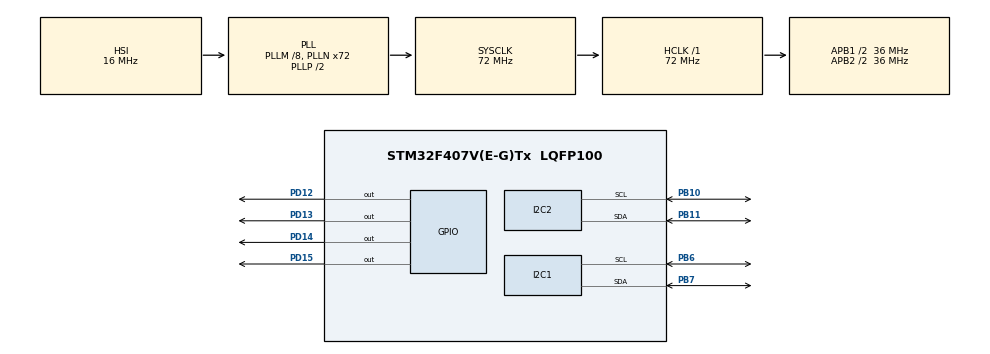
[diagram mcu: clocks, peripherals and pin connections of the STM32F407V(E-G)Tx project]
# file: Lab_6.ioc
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Mcu.Family=STM32F4
Mcu.Name=STM32F407V(E-G)Tx
Mcu.Package=LQFP100
NVIC.I2C1_ER_IRQn=true\:0\:0\:false\:true\:true\:2\:true\:true\:true
NVIC.I2C1_EV_IRQn=true\:0\:0\:false\:true\:true\:1\:true\:true\:true
NVIC.I2C2_ER_IRQn=true\:0\:0\:false\:false\:true\:true\:true\:true
NVIC.I2C2_EV_IRQn=true\:0\:0\:false\:false\:true\:true\:true\:true
NVIC.PriorityGroup=NVIC_PRIORITYGROUP_0
PA13.Mode=Trace_Asynchronous_SW
PA13.Signal=SYS_JTMS-SWDIO
PA14.Mode=Trace_Asynchronous_SW
PA14.Signal=SYS_JTCK-SWCLK
PB10.GPIO_Pu=GPIO_PULLUP
PB10.Mode=I2C
PB10.Signal=I2C2_SCL
PB11.GPIO_Pu=GPIO_PULLUP
PB11.Mode=I2C
PB11.Signal=I2C2_SDA
PB3.Mode=Trace_Asynchronous_SW
PB3.Signal=SYS_JTDO-SWO
PB6.GPIO_Mode=GPIO_MODE_AF_OD
PB6.GPIO_Pu=GPIO_PULLUP
PB6.GPIO_Speed=GPIO_SPEED_FREQ_VERY_HIGH
PB6.Mode=I2C
PB6.Signal=I2C1_SCL
PB7.GPIO_Mode=GPIO_MODE_AF_OD
PB7.GPIO_Pu=GPIO_PULLUP
PB7.GPIO_Speed=GPIO_SPEED_FREQ_VERY_HIGH
PB7.Mode=I2C
PB7.Signal=I2C1_SDA
PD12.Signal=GPIO_Output
PD13.Signal=GPIO_Output
PD14.Signal=GPIO_Output
PD15.Signal=GPIO_Output
ProjectManager.HeapSize=0x200
ProjectManager.StackSize=0x400
ProjectManager.TargetToolchain=STM32CubeIDE
RCC.48MHZClocksFreq_Value=20571428.57142857
RCC.AHBFreq_Value=72000000
RCC.APB1CLKDivider=RCC_HCLK_DIV2
RCC.APB1Freq_Value=36000000
RCC.APB1TimFreq_Value=72000000
RCC.APB2CLKDivider=RCC_HCLK_DIV2
RCC.APB2Freq_Value=36000000
RCC.APB2TimFreq_Value=72000000
RCC.CortexFreq_Value=72000000
RCC.HCLKFreq_Value=72000000
RCC.HSE_VALUE=8000000
RCC.HSI_VALUE=16000000
RCC.PLLM=8
RCC.PLLN=72
RCC.PLLQ=7
RCC.SYSCLKFreq_VALUE=72000000
RCC.SYSCLKSource=RCC_SYSCLKSOURCE_PLLCLK
RCC.VCOOutputFreq_Value=144000000
board=STM32F407G-DISC1

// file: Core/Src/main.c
/* USER CODE BEGIN Header */
/**
  ******************************************************************************
  * @file           : main.c
  * @brief          : Main program body
  ******************************************************************************
  * @attention
  *
  * Copyright (c) 2024 STMicroelectronics.
  * All rights reserved.
  *
  * This software is licensed under terms that can be found in the LICENSE file
  * in the root directory of this software component.
  * If no LICENSE file comes with this software, it is provided AS-IS.
  *
  ******************************************************************************
  */
/* USER CODE END Header */
#include "main.h"

I2C_HandleTypeDef hi2c1;
I2C_HandleTypeDef hi2c2;

/* USER CODE BEGIN PV */
uint8_t receivedData;
/* USER CODE END PV */

void SystemClock_Config(void);
static void MX_GPIO_Init(void);
static void MX_I2C1_Init(void);
static void MX_I2C2_Init(void);
static void MX_NVIC_Init(void);

int main(void)
{

  /* MCU Configuration--------------------------------------------------------*/

  /* Reset of all peripherals, Initializes the Flash interface and the Systick. */
  HAL_Init();

  /* Configure the system clock */
  SystemClock_Config();

  /* Initialize all configured peripherals */
  MX_GPIO_Init();
  MX_I2C1_Init();
  MX_I2C2_Init();

  /* Initialize interrupts */
  MX_NVIC_Init();
  /* USER CODE BEGIN 2 */
  //HAL_I2C_EnableListen_IT(&hi2c1);
  /* USER CODE END 2 */

  /* Infinite loop */
  while (1)
  {

    /* USER CODE BEGIN 3 */
	  if(HAL_I2C_Slave_Receive(&hi2c1, (uint8_t *)&receivedData, sizeof(receivedData),1000)== HAL_OK){
		  GPIOD->ODR &= ~(GPIO_ODR_OD12 |GPIO_ODR_OD13 |GPIO_ODR_OD14 |GPIO_ODR_OD15 );
		  GPIOD->ODR |= (receivedData<<12);
	  }
//	  else{
//		  HAL_GPIO_WritePin(GPIOD, GPIO_PIN_12, RESET);
//		  HAL_GPIO_WritePin(GPIOD, GPIO_PIN_14, RESET);
//		  HAL_GPIO_WritePin(GPIOD, GPIO_PIN_15, RESET);
//		  HAL_GPIO_TogglePin(GPIOD, GPIO_PIN_13);
//	  }
  }
  /* USER CODE END 3 */
}

void SystemClock_Config(void)
{
  RCC_OscInitTypeDef RCC_OscInitStruct = {0};
  RCC_ClkInitTypeDef RCC_ClkInitStruct = {0};

  /** Configure the main internal regulator output voltage
  */
  __HAL_RCC_PWR_CLK_ENABLE();
  __HAL_PWR_VOLTAGESCALING_CONFIG(PWR_REGULATOR_VOLTAGE_SCALE1);

  /** Initializes the RCC Oscillators according to the specified parameters
  * in the RCC_OscInitTypeDef structure.
  */
  RCC_OscInitStruct.OscillatorType = RCC_OSCILLATORTYPE_HSI;
  RCC_OscInitStruct.HSIState = RCC_HSI_ON;
  RCC_OscInitStruct.HSICalibrationValue = RCC_HSICALIBRATION_DEFAULT;
  RCC_OscInitStruct.PLL.PLLState = RCC_PLL_ON;
  RCC_OscInitStruct.PLL.PLLSource = RCC_PLLSOURCE_HSI;
  RCC_OscInitStruct.PLL.PLLM = 8;
  RCC_OscInitStruct.PLL.PLLN = 72;
  RCC_OscInitStruct.PLL.PLLP = RCC_PLLP_DIV2;
  RCC_OscInitStruct.PLL.PLLQ = 7;
  if (HAL_RCC_OscConfig(&RCC_OscInitStruct) != HAL_OK)
  {
    Error_Handler();
  }

  /** Initializes the CPU, AHB and APB buses clocks
  */
  RCC_ClkInitStruct.ClockType = RCC_CLOCKTYPE_HCLK|RCC_CLOCKTYPE_SYSCLK
                              |RCC_CLOCKTYPE_PCLK1|RCC_CLOCKTYPE_PCLK2;
  RCC_ClkInitStruct.SYSCLKSource = RCC_SYSCLKSOURCE_PLLCLK;
  RCC_ClkInitStruct.AHBCLKDivider = RCC_SYSCLK_DIV1;
  RCC_ClkInitStruct.APB1CLKDivider = RCC_HCLK_DIV2;
  RCC_ClkInitStruct.APB2CLKDivider = RCC_HCLK_DIV2;

  if (HAL_RCC_ClockConfig(&RCC_ClkInitStruct, FLASH_LATENCY_2) != HAL_OK)
  {
    Error_Handler();
  }
}

/**
  * @brief NVIC Configuration.
  * @retval None
  */
static void MX_NVIC_Init(void)
{
  /* I2C1_EV_IRQn interrupt configuration */
  HAL_NVIC_SetPriority(I2C1_EV_IRQn, 0, 0);
  HAL_NVIC_EnableIRQ(I2C1_EV_IRQn);
  /* I2C1_ER_IRQn interrupt configuration */
  HAL_NVIC_SetPriority(I2C1_ER_IRQn, 0, 0);
  HAL_NVIC_EnableIRQ(I2C1_ER_IRQn);
}

static void MX_I2C1_Init(void)
{

  hi2c1.Instance = I2C1;
  hi2c1.Init.ClockSpeed = 100000;
  hi2c1.Init.DutyCycle = I2C_DUTYCYCLE_2;
  hi2c1.Init.OwnAddress1 = 0xFA;
  hi2c1.Init.AddressingMode = I2C_ADDRESSINGMODE_7BIT;
  hi2c1.Init.DualAddressMode = I2C_ UALADDRESS_DISABLE;
  hi2c1.Init.OwnAddress2 = 0;
  hi2c1.Init.GeneralCallMode = I2C_GENERALCALL_DISABLE;
  hi2c1.Init.NoStretchMode = I2C_NOSTRETCH_DISABLE;
  if (HAL_I2C_Init(&hi2c1) != HAL_OK)
  {
    Error_Handler();
  }

}

static void MX_I2C2_Init(void)
{

  hi2c2.Instance = I2C2;
  hi2c2.Init.ClockSpeed = 100000;
  hi2c2.Init.DutyCycle = I2C_DUTYCYCLE_2;
  hi2c2.Init.OwnAddress1 = 0xFA;
  hi2c2.Init.AddressingMode = I2C_ADDRESSINGMODE_7BIT;
  hi2c2.Init.DualAddressMode = I2C_DUALADDRESS_DISABLE;
  hi2c2.Init.OwnAddress2 = 0;
  hi2c2.Init.GeneralCallMode = I2C_GENERALCALL_DISABLE;
  hi2c2.Init.NoStretchMode = I2C_NOSTRETCH_DISABLE;
  if (HAL_I2C_Init(&hi2c2) != HAL_OK)
  {
    Error_Handler();
  }

}

static void MX_GPIO_Init(void)
{
  GPIO_InitTypeDef GPIO_InitStruct = {0};

  /* GPIO Ports Clock Enable */
  __HAL_RCC_GPIOB_CLK_ENABLE();
  __HAL_RCC_GPIOD_CLK_ENABLE();
  __HAL_RCC_GPIOA_CLK_ENABLE();

  /*Configure GPIO pin Output Level */
  HAL_GPIO_WritePin(GPIOD, GPIO_PIN_12|GPIO_PIN_13|GPIO_PIN_14|GPIO_PIN_15, GPIO_PIN_RESET);

  /*Configure GPIO pins : PD12 PD13 PD14 PD15 */
  GPIO_InitStruct.Pin = GPIO_PIN_12|GPIO_PIN_13|GPIO_PIN_14|GPIO_PIN_15;
  GPIO_InitStruct.Mode = GPIO_MODE_OUTPUT_PP;
  GPIO_InitStruct.Pull = GPIO_NOPULL;
  GPIO_InitStruct.Speed = GPIO_SPEED_FREQ_LOW;
  HAL_GPIO_Init(GPIOD, &GPIO_InitStruct);

}

void Error_Handler(void)
{
  __disable_irq();
  while (1)
  {
  }
}
